AUTOSAR XML (schema 4-0-3)
package /ComponentTypes
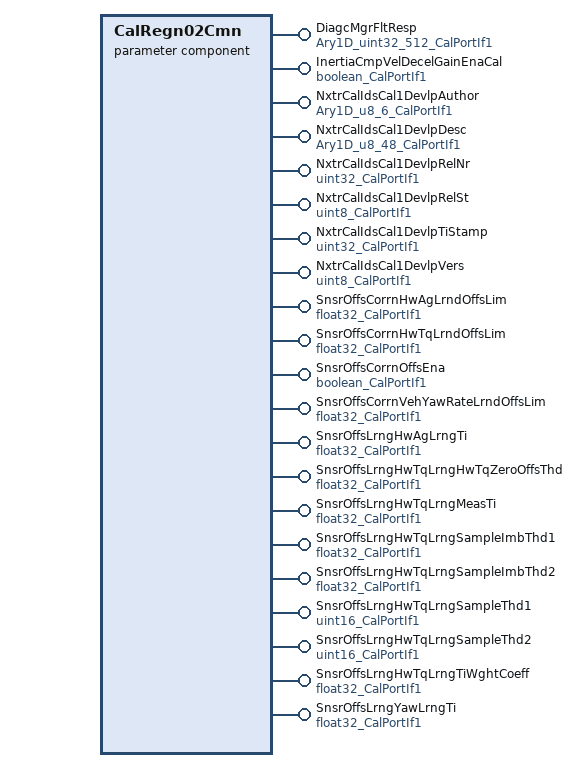
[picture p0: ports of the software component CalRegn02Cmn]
  parameter sw component type CalRegn02Cmn
    21 x provide port:
      DiagcMgrFltResp: parameter-provide-com-spec{init-value=[0, 2147487488, 2147487488, 2147487488, 2147487488, 2147487488, 2147487488, 2147487488, 2147487488, 2147487488, 2147487488, 2147487488, 2147487488, 2147487488, 2147487488, 2147487488, 2147487488, 2147487488, 2147487488, 2147487488, 2147487488, 2147487488, 2147487488, 2147487488, 2147487488, 2147487488, 2147487488, 2147487488, 2147487488, 2147487488, 2147487488, 2147487488, 2147487488, 2147487488, 2147487488, 2147487488, 2147487488, 2147487488, 2147487488, 2147487488, 2147487488, 2147487488, 2147487488, 2147487488, 2147487488, 2147487488, 2147487488, 2147487488, 2147487488, 2147487488, 2147487488, 2147487488, 2147487488, 2147487488, 2147487488, 2147487488, 2147487488, 2147487488, 2147487488, 2147487488, 2147487488, 2147487488, 2147487488, 2147487488, 2147487488, 2147487488, 2147487488, 2147487488, 2147487488, 2147487488, 2147487488, 2147487488, 2147487488, 2147487488, 2147487488, 2147487488, 2147487488, 2147487488, 2147487488, 2147487488, 2147487488, 2147487488, 2147487488, 2147487488, 2147487488, 2147487488, 2147487488, 2147487488, 2147487488, 2147487488, 2147487488, 2147487488, 2147487488, 2147487488, 2147487488, 2147487488, 2147487488, 2147487488, 2147487488, 2147487488, 2147487488, 2147487488, 2147487488, 2147487488, 2147487488, 2147487488, 2147487488, 2147487488, 2147487488, 2147487488, 2147487488, 2147487488, 2147487488, 2147487488, 2147487488, 2147487488, 2147487488, 2147487488, 2147487488, 2147487488, 2147487488, 2147487488, 2147487488, 2147487488, 2147487488, 2147487488, 2147487488, 2147487488, 2147487488, 2147487488, 2147487488, 2147487488, 2147487488, 2147487488, 2147487488, 2147487488, 2147487488, 2147487488, 2147487488, 2147487488, 2147487488, 2147487488, 2147487488, 2147487488, 2147487488, 2147487488, 2147487488, 2147487488, 2147487488, 2147487488, 2147487488, 2147487488, 2147487488, 2147487488, 2147487488, 2147487488, 2147487488, 2147487488, 2147487488, 2147487488, 2147487488, 2147487488, 2147487488, 2147487488, 2147487488, 2147487488, 2147487488, 2147487488, 2147487488, 2147487488, 2147487488, 2147487488, 2147487488, 2147487488, 2147487488, 2147487488, 2147487488, 2147487488, 2147487488, 2147487488, 2147487488, 2147487488, 2147487488, 2147487488, 2147487488, 2147487488, 2147487488, 2147487488, 2147487488, 2147487488, 2147487488, 2147487488, 2147487488, 2147487488, 2147487488, 2147487488, 2147487488, 2147487488, 2147487488, 2147487488, 2147487488, 2147487488, 2147487488, 2147487488, 2147487488, 2147487488, 2147487488, 2147487488, 2147487488, 2147487488, 2147487488, 2147487488, 2147487488, 2147487488, 2147487488, 2147487488, 2147487488, 2147487488, 2147487488, 2147487488, 2147487488, 2147487488, 2147487488, 2147487488, 2147487488, 2147487488, 2147487488, 2147487488, 2147487488, 2147487488, 2147487488, 2147487488, 2147487488, 2147487488, 2147487488, 2147487488, 2147487488, 2147487488, 2147487488, 2147487488, 2147487488, 2147487488, 2147487488, 2147487488, 2147487488, 2147487488, 2147487488, 2147487488, 2147487488, 2147487488, 2147487488, 2147487488, 2147487488, 2147487488, 2147487488, 2147487488, 2147487488, 2147487488, 2147487488, 2147487488, 2147487488, 2147487488, 2147487488, 2147487488, 2147487488, 2147487488, 2147487488, 2147487488, 2147487488, 2147487488, 2147487488, 2147487488, 2147487488, 2147487488, 2147487488, 2147487488, 2147487488, 2147487488, 2147487488, 2147487488, 2147487488, 2147487488, 2147487488, 2147487488, 2147487488, 2147487488, 2147487488, 2147487488, 2147487488, 2147487488, 2147487488, 2147487488, 2147487488, 2147487488, 2147487488, 2147487488, 2147487488, 2147487488, 2147487488, 2147487488, 2147487488, 2147487488, 2147487488, 2147487488, 2147487488, 2147487488, 2147487488, 2147487488, 2147487488, 2147487488, 2147487488, 2147487488, 2147487488, 2147487488, 2147487488, 2147487488, 2147487488, 2147487488, 2147487488, 2147487488, 2147487488, 2147487488, 2147487488, 2147487488, 2147487488, 2147487488, 2147487488, 2147487488, 2147487488, 2147487488, 2147487488, 2147487488, 2147487488, 2147487488, 2147487488, 2147487488, 2147487488, 2147487488, 2147487488, 2147487488, 2147487488, 2147487488, 2147487488, 2147487488, 2147487488, 2147487488, 2147487488, 2147487488, 2147487488, 2147487488, 2147487488, 2147487488, 2147487488, 2147487488, 2147487488, 2147487488, 2147487488, 2147487488, 2147487488, 2147487488, 2147487488, 2147487488, 2147487488, 2147487488, 2147487488, 2147487488, 2147487488, 2147487488, 2147487488, 2147487488, 2147487488, 2147487488, 2147487488, 2147487488, 2147487488, 2147487488, 2147487488, 2147487488, 2147487488, 2147487488, 2147487488, 2147487488, 2147487488, 2147487488, 2147487488, 2147487488, 2147487488, 2147487488, 2147487488, 2147487488, 2147487488, 2147487488, 2147487488, 2147487488, 2147487488, 2147487488, 2147487488, 2147487488, 2147487488, 2147487488, 2147487488, 2147487488, 2147487488, 2147487488, 2147487488, 2147487488, 2147487488, 2147487488, 2147487488, 2147487488, 2147487488, 2147487488, 2147487488, 2147487488, 2147487488, 2147487488, 2147487488, 2147487488, 2147487488, 2147487488, 2147487488, 2147487488, 2147487488, 2147487488, 2147487488, 2147487488, 2147487488, 2147487488, 2147487488, 2147487488, 2147487488, 2147487488, 2147487488, 2147487488, 2147487488, 2147487488, 2147487488, 2147487488, 2147487488, 2147487488, 2147487488, 2147487488, 2147487488, 2147487488, 2147487488, 2147487488, 2147487488, 2147487488, 2147487488, 2147487488, 2147487488, 2147487488, 2147487488, 2147487488, 2147487488, 2147487488, 2147487488, 2147487488, 2147487488, 2147487488, 2147487488, 2147487488, 2147487488, 2147487488, 2147487488, 2147487488, 2147487488, 2147487488, 2147487488, 2147487488, 2147487488, 2147487488, 2147487488, 2147487488, 2147487488, 2147487488, 2147487488, 2147487488, 2147487488, 2147487488, 2147487488, 2147487488, 2147487488, 2147487488, 2147487488, 2147487488, 2147487488, 2147487488, 2147487488, 2147487488, 2147487488, 2147487488, 2147487488, 2147487488, 2147487488, 2147487488, 2147487488, 2147487488, 2147487488, 2147487488, 2147487488, 2147487488, 2147487488, 2147487488, 2147487488, 2147487488, 2147487488, 2147487488, 2147487488, 2147487488, 2147487488, 2147487488], parameter=Ary1D}, provided-interface=Ary1D_uint32_512_CalPortIf1
      InertiaCmpVelDecelGainEnaCal: parameter-provide-com-spec{init-value=0, parameter=Logl}, provided-interface=boolean_CalPortIf1
      NxtrCalIdsCal1DevlpAuthor: parameter-provide-com-spec{init-value=6 x 0, parameter=Ary1D}, provided-interface=Ary1D_u8_6_CalPortIf1
      NxtrCalIdsCal1DevlpDesc: parameter-provide-com-spec{init-value=48 x 0, parameter=Ary1D}, provided-interface=Ary1D_u8_48_CalPortIf1
      NxtrCalIdsCal1DevlpRelNr: parameter-provide-com-spec{init-value=0, parameter=Val}, provided-interface=uint32_CalPortIf1
      NxtrCalIdsCal1DevlpRelSt: parameter-provide-com-spec{init-value=0, parameter=Val}, provided-interface=uint8_CalPortIf1
      NxtrCalIdsCal1DevlpTiStamp: parameter-provide-com-spec{init-value=0, parameter=Val}, provided-interface=uint32_CalPortIf1
      NxtrCalIdsCal1DevlpVers: parameter-provide-com-spec{init-value=0, parameter=Val}, provided-interface=uint8_CalPortIf1
      SnsrOffsCorrnHwAgLrndOffsLim: parameter-provide-com-spec{init-value=5, parameter=Val}, provided-interface=float32_CalPortIf1
      SnsrOffsCorrnHwTqLrndOffsLim: parameter-provide-com-spec{init-value=0.5, parameter=Val}, provided-interface=float32_CalPortIf1
      SnsrOffsCorrnOffsEna: parameter-provide-com-spec{init-value=0, parameter=Logl}, provided-interface=boolean_CalPortIf1
      SnsrOffsCorrnVehYawRateLrndOffsLim: parameter-provide-com-spec{init-value=5, parameter=Val}, provided-interface=float32_CalPortIf1
      SnsrOffsLrngHwAgLrngTi: parameter-provide-com-spec{init-value=1000, parameter=Val}, provided-interface=float32_CalPortIf1
      SnsrOffsLrngHwTqLrngHwTqZeroOffsThd: parameter-provide-com-spec{init-value=0.15, parameter=Val}, provided-interface=float32_CalPortIf1
      SnsrOffsLrngHwTqLrngMeasTi: parameter-provide-com-spec{init-value=3, parameter=Val}, provided-interface=float32_CalPortIf1
      SnsrOffsLrngHwTqLrngSampleImbThd1: parameter-provide-com-spec{init-value=0.6667, parameter=Val}, provided-interface=float32_CalPortIf1
      SnsrOffsLrngHwTqLrngSampleImbThd2: parameter-provide-com-spec{init-value=0.3334, parameter=Val}, provided-interface=float32_CalPortIf1
      SnsrOffsLrngHwTqLrngSampleThd1: parameter-provide-com-spec{init-value=20, parameter=Val}, provided-interface=uint16_CalPortIf1
      SnsrOffsLrngHwTqLrngSampleThd2: parameter-provide-com-spec{init-value=50, parameter=Val}, provided-interface=uint16_CalPortIf1
      SnsrOffsLrngHwTqLrngTiWghtCoeff: parameter-provide-com-spec{init-value=1, parameter=Val}, provided-interface=float32_CalPortIf1
      SnsrOffsLrngYawLrngTi: parameter-provide-com-spec{init-value=100, parameter=Val}, provided-interface=float32_CalPortIf1
